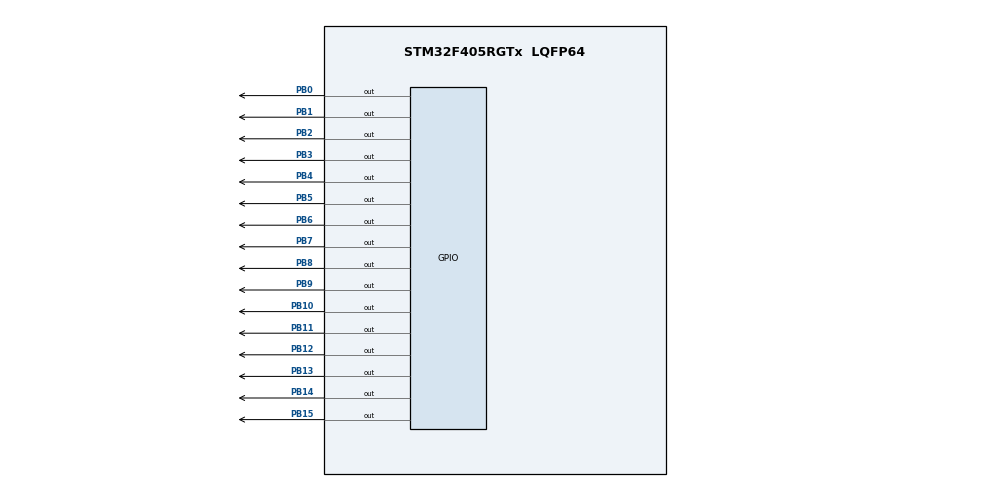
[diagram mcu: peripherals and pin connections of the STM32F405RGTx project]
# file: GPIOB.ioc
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Mcu.Family=STM32F4
Mcu.Name=STM32F405RGTx
Mcu.Package=LQFP64
NVIC.PriorityGroup=NVIC_PRIORITYGROUP_4
PA13.Mode=Serial_Wire
PA13.Signal=SYS_JTMS-SWDIO
PA14.Mode=Serial_Wire
PA14.Signal=SYS_JTCK-SWCLK
PB0.Signal=GPIO_Output
PB1.Signal=GPIO_Output
PB10.Signal=GPIO_Output
PB11.Signal=GPIO_Output
PB12.Signal=GPIO_Output
PB13.Signal=GPIO_Output
PB14.Signal=GPIO_Output
PB15.Signal=GPIO_Output
PB2.Signal=GPIO_Output
PB3.Signal=GPIO_Output
PB4.Signal=GPIO_Output
PB5.Signal=GPIO_Output
PB6.Signal=GPIO_Output
PB7.Signal=GPIO_Output
PB8.Signal=GPIO_Output
PB9.Signal=GPIO_Output
PH0-OSC_IN.Mode=HSE-External-Oscillator
PH0-OSC_IN.Signal=RCC_OSC_IN
PH1-OSC_OUT.Mode=HSE-External-Oscillator
PH1-OSC_OUT.Signal=RCC_OSC_OUT
ProjectManager.HeapSize=0x200
ProjectManager.StackSize=0x400
ProjectManager.TargetToolchain=STM32CubeIDE
RCC.48MHZClocksFreq_Value=48000000
RCC.AHBFreq_Value=168000000
RCC.APB1CLKDivider=RCC_HCLK_DIV4
RCC.APB1Freq_Value=42000000
RCC.APB1TimFreq_Value=84000000
RCC.APB2CLKDivider=RCC_HCLK_DIV2
RCC.APB2Freq_Value=84000000
RCC.APB2TimFreq_Value=168000000
RCC.CortexFreq_Value=168000000
RCC.HCLKFreq_Value=168000000
RCC.HSE_VALUE=16000000
RCC.HSI_VALUE=16000000
RCC.LSE_VALUE=32768
RCC.PLLM=8
RCC.PLLN=168
RCC.PLLQ=7
RCC.PLLSourceVirtual=RCC_PLLSOURCE_HSE
RCC.SYSCLKFreq_VALUE=168000000
RCC.SYSCLKSource=RCC_SYSCLKSOURCE_PLLCLK
RCC.VCOOutputFreq_Value=336000000
board=custom

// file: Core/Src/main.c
/* USER CODE BEGIN Header */
/**
  ******************************************************************************
  * @file           : main.c
  * @brief          : Main program body
  ******************************************************************************
  * @attention
  *
  * Copyright (c) 2025 STMicroelectronics.
  * All rights reserved.
  *
  * This software is licensed under terms that can be found in the LICENSE file
  * in the root directory of this software component.
  * If no LICENSE file comes with this software, it is provided AS-IS.
  *
  ******************************************************************************
  */
/* USER CODE END Header */
#include "main.h"

void SystemClock_Config(void);
static void MX_GPIO_Init(void);

int main(void)
{

  /* MCU Configuration--------------------------------------------------------*/

  /* Reset of all peripherals, Initializes the Flash interface and the Systick. */
  LL_APB2_GRP1_EnableClock(LL_APB2_GRP1_PERIPH_SYSCFG);
  LL_APB1_GRP1_EnableClock(LL_APB1_GRP1_PERIPH_PWR);

  /* System interrupt init*/
  NVIC_SetPriorityGrouping(NVIC_PRIORITYGROUP_4);

  /* SysTick_IRQn interrupt configuration */
  NVIC_SetPriority(SysTick_IRQn, NVIC_EncodePriority(NVIC_GetPriorityGrouping(),15, 0));

  /* Configure the system clock */
  SystemClock_Config();

  /* Initialize all configured peripherals */
  MX_GPIO_Init();

  /* Infinite loop */
  /* USER CODE BEGIN WHILE */
  int cnt = 0;
  int step = 1;
  while (1)
  {
	  // Reset GPIOB
	  GPIOB->BSRR = 0xffff << 16;
      // Set pin according to cnt
	  GPIOB->BSRR = (1 << cnt);

	  cnt += step;

	  if(cnt > 14) {
		  step = -1;
	  }
	  else if(cnt < 1) {
		  step = 1;
	  }

	  LL_mDelay(20);

    /* USER CODE END WHILE */

  }
}

void SystemClock_Config(void)
{
  LL_FLASH_SetLatency(LL_FLASH_LATENCY_5);
  while(LL_FLASH_GetLatency()!= LL_FLASH_LATENCY_5)
  {
  }
  LL_PWR_SetRegulVoltageScaling(LL_PWR_REGU_VOLTAGE_SCALE1);
  LL_RCC_HSE_Enable();

   /* Wait till HSE is ready */
  while(LL_RCC_HSE_IsReady() != 1)
  {

  }
  LL_RCC_PLL_ConfigDomain_SYS(LL_RCC_PLLSOURCE_HSE, LL_RCC_PLLM_DIV_8, 168, LL_RCC_PLLP_DIV_2);
  LL_RCC_PLL_Enable();

   /* Wait till PLL is ready */
  while(LL_RCC_PLL_IsReady() != 1)
  {

  }
  while (LL_PWR_IsActiveFlag_VOS() == 0)
  {
  }
  LL_RCC_SetAHBPrescaler(LL_RCC_SYSCLK_DIV_1);
  LL_RCC_SetAPB1Prescaler(LL_RCC_APB1_DIV_4);
  LL_RCC_SetAPB2Prescaler(LL_RCC_APB2_DIV_2);
  LL_RCC_SetSysClkSource(LL_RCC_SYS_CLKSOURCE_PLL);

   /* Wait till System clock is ready */
  while(LL_RCC_GetSysClkSource() != LL_RCC_SYS_CLKSOURCE_STATUS_PLL)
  {

  }
  LL_Init1msTick(168000000);
  LL_SetSystemCoreClock(168000000);
}

static void MX_GPIO_Init(void)
{
  LL_GPIO_InitTypeDef GPIO_InitStruct = {0};

  /* GPIO Ports Clock Enable */
  LL_AHB1_GRP1_EnableClock(LL_AHB1_GRP1_PERIPH_GPIOH);
  LL_AHB1_GRP1_EnableClock(LL_AHB1_GRP1_PERIPH_GPIOB);
  LL_AHB1_GRP1_EnableClock(LL_AHB1_GRP1_PERIPH_GPIOA);

  /**/
  LL_GPIO_ResetOutputPin(GPIOB, LL_GPIO_PIN_0|LL_GPIO_PIN_1|LL_GPIO_PIN_2|LL_GPIO_PIN_10
                          |LL_GPIO_PIN_11|LL_GPIO_PIN_12|LL_GPIO_PIN_13|LL_GPIO_PIN_14
                          |LL_GPIO_PIN_15|LL_GPIO_PIN_3|LL_GPIO_PIN_4|LL_GPIO_PIN_5
                          |LL_GPIO_PIN_6|LL_GPIO_PIN_7|LL_GPIO_PIN_8|LL_GPIO_PIN_9);

  /**/
  GPIO_InitStruct.Pin = LL_GPIO_PIN_0|LL_GPIO_PIN_1|LL_GPIO_PIN_2|LL_GPIO_PIN_10
                          |LL_GPIO_PIN_11|LL_GPIO_PIN_12|LL_GPIO_PIN_13|LL_GPIO_PIN_14
                          |LL_GPIO_PIN_15|LL_GPIO_PIN_3|LL_GPIO_PIN_4|LL_GPIO_PIN_5
                          |LL_GPIO_PIN_6|LL_GPIO_PIN_7|LL_GPIO_PIN_8|LL_GPIO_PIN_9;
  GPIO_InitStruct.Mode = LL_GPIO_MODE_OUTPUT;
  GPIO_InitStruct.Speed = LL_GPIO_SPEED_FREQ_LOW;
  GPIO_InitStruct.OutputType = LL_GPIO_OUTPUT_PUSHPULL;
  GPIO_InitStruct.Pull = LL_GPIO_PULL_NO;
  LL_GPIO_Init(GPIOB, &GPIO_InitStruct);

}

void Error_Handler(void)
{
  __disable_irq();
  while (1)
  {
  }
}
